# XMC4300 register map
Vendor: Infineon; File version: 0.5.1 (Superset device XMC4800)
CPU: CM4 r2p0, little endian, MPU, FPU, 6 interrupt priority bits
Registers are 32-bit, read-write, reset 0x0 unless marked. A register's access mark holds for its fields unless they carry their own. Offsets are from the block's base; [hi:lo] are bit positions.

## ECAT0_FMMU0 — EtherCAT 0
Base 0x54010600
Same registers: ECAT0_FMMU1 0x54010610, ECAT0_FMMU2 0x54010620, ECAT0_FMMU3 0x54010630, ECAT0_FMMU4 0x54010640, ECAT0_FMMU5 0x54010650, ECAT0_FMMU6 0x54010660, ECAT0_FMMU7 0x54010670
0x00 FMMU_L_START_ADR ro — Logical Start address FMMU
  [31:0] L_START_ADDR — Logical start address within the EtherCAT Address Space
0x04 FMMU_LEN 16-bit ro — Length FMMU 0
  [15:0] OFFSET — Offset from the first logical FMMU Byte to the last FMMU Byte + 1
0x06 FMMU_L_START_BIT 8-bit ro — Start bit FMMU 0 in logical address space
  [2:0] L_START_BIT — Logical starting bit that shall be mapped
0x07 FMMU_L_STOP_BIT 8-bit ro — Stop bit FMMU 0 in logical address space
  [2:0] L_STOP_BIT — Last logical bit that shall be mapped
0x08 FMMU_P_START_ADR 16-bit ro — Ph0sical Start address FMMU y
  [15:0] P_START_ADDR — Physical Start Address
0x0A FMMU_P_START_BIT 8-bit ro — Ph0sical Start bit FMMU y
  [2:0] P_START_BIT — Physical starting bit as target of logical start bit mapping
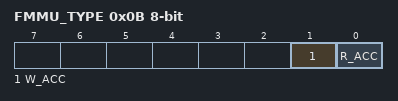
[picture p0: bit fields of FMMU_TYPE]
0x0B FMMU_TYPE 8-bit ro — T0pe FMMU y
  [1] W_ACC — Write Access
    0=Ignore mapping for write accesses; 1=Use mapping for write accesses
  [0] R_ACC — Read Access
    0=Ignore mapping for read accesses; 1=Use mapping for read accesses
0x0C FMMU_ACT 8-bit ro — Activate FMMU 0
  [0] ACT — FMMU Activation
    0=FMMU deactivated; 1=FMMU activated. FMMU checks logical addressed blocks to be mapped according to mapping configured

## ECAT0_SM0 — EtherCAT 0
Base 0x54010800
Same registers: ECAT0_SM1 0x54010808, ECAT0_SM2 0x54010810, ECAT0_SM3 0x54010818, ECAT0_SM4 0x54010820, ECAT0_SM5 0x54010828, ECAT0_SM6 0x54010830, ECAT0_SM7 0x54010838
0x00 SM_P_START_ADR 16-bit ro — Physical Start Address SyncManager 0
  [15:0] FIRST_BYTE — Specifies first byte that will be handled by SyncManager
0x02 SM_LEN 16-bit ro — Length SyncManager 0
  [15:0] NO_BYTES — Number of bytes assigned to SyncManager
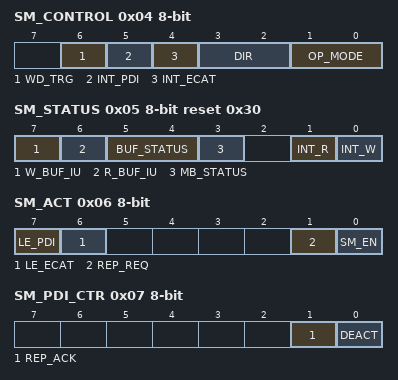
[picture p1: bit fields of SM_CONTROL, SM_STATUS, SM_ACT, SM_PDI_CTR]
0x04 SM_CONTROL 8-bit ro — Control Register SyncManager 0
  [6] WD_TRG — Watchdog Trigger Enable
    0=Disabled; 1=Enabled
  [5] INT_PDI — Interrupt in PDI Event Request Register
    0=Disabled; 1=Enabled
  [4] INT_ECAT — Interrupt in ECAT Event Request Register
    0=Disabled; 1=Enabled
  [3:2] DIR — Direction
    0=Read: ECAT read access, PDI write access; 1=Write: ECAT write access, PDI read access
  [1:0] OP_MODE — Operation Mode
    0=Buffered (3 buffer mode); 2=Mailbox (Single buffer mode)
0x05 SM_STATUS 8-bit ro reset 0x30 — Status Register SyncManager 0
  [7] W_BUF_IU — Write buffer in use (opened)
    0=buffer not in use; 1=buffer in use
  [6] R_BUF_IU — Read buffer in use (opened)
    0=buffer not in use; 1=buffer in use
  [5:4] BUF_STATUS — Buffered mode: buffer status (last written buffer)
    0=1. buffer; 1=2. buffer; 2=3. buffer; 3=(no buffer written)
  [3] MB_STATUS — Mailbox mode: mailbox status
    0=Mailbox empty; 1=Mailbox full
  [1] INT_R — Interrupt Read
    0=Interrupt cleared after first byte of buffer was written; 1=Interrupt after buffer was completely and successful read
  [0] INT_W — Interrupt Write
    0=Interrupt cleared after first byte of buffer was read; 1=Interrupt after buffer was completely and successfully written
0x06 SM_ACT 8-bit ro — Activate SyncManager 0
  [7] LE_PDI — LatchEvent PDI
    0=No; 1=Generate Latch events if PDI issues a buffer exchange or if PDI accesses buffer start address
  [6] LE_ECAT — LatchEvent ECAT
    0=No; 1=Generate Latch event if EtherCAT master issues a buffer exchange
  [1] REP_REQ — Repeat Request
  [0] SM_EN — SyncManager Enable/Disable
    0=Disable: Access to Memory without SyncManager control; 1=Enable: SyncManager is active and controls Memory area set in configuration
0x07 SM_PDI_CTR 8-bit — PDI Control SyncManager 0
  [1] REP_ACK — Repeat Ack
  [0] DEACT — Deactivate SyncManager
    0=Read 0 for Normal operation, SyncManager activated, write 0 for Activate SyncManager; 1=Read 1 for SyncManager deactivated and reset SyncManager locks access to Memory area, write 1 for Request SyncManager deactivation
